# GD32F4xx register map
File version: 1.0
CPU: CM4 r2p1, little endian, MPU, FPU, 4 interrupt priority bits
Registers are 32-bit, read-write, reset 0x0 unless marked. A register's access mark holds for its fields unless they carry their own. Offsets are from the block's base; [hi:lo] are bit positions.

## I2C0 — Inter integrated circuit
Base 0x40005400
Same registers: I2C1 0x40005800, I2C2 0x40005C00
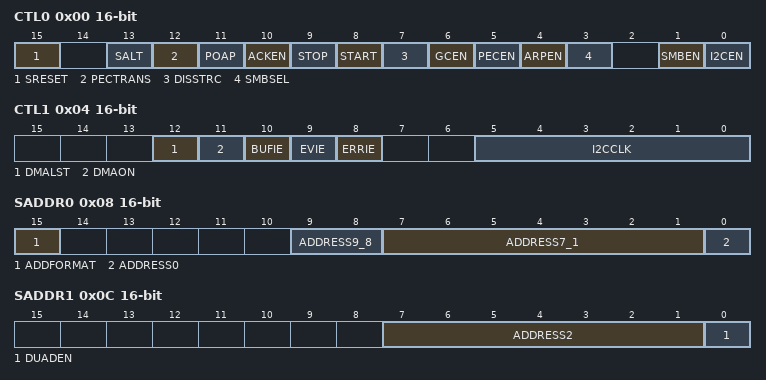
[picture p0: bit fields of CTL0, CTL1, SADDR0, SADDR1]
0x00 CTL0 16-bit — Control register 0
  [15] SRESET — Software reset
  [13] SALT — SMBus alert
  [12] PECTRANS — PEC Transfer
  [11] POAP — Position of ACK and PEC when receiving
  [10] ACKEN — Whether or not to send an ACK
  [9] STOP — Generate a STOP condition on I2C bus
  [8] START — Generate a START condition on I2C bus
  [7] DISSTRC — Whether to stretch SCL low when data is not ready in slave mode
  [6] GCEN — Whether or not to response to a General Call (0x00)
  [5] PECEN — PEC Calculation Switch
  [4] ARPEN — ARP protocol in SMBus switch
  [3] SMBSEL — SMBusType Selection
  [1] SMBEN — SMBus/I2C mode switch
  [0] I2CEN — I2C peripheral enable
0x04 CTL1 16-bit — Control register 1
  [12] DMALST — Flag indicating DMA last transfer
  [11] DMAON — DMA mode switch
  [10] BUFIE — Buffer interrupt enable
  [9] EVIE — Event interrupt enable
  [8] ERRIE — Error interrupt enable
  [5:0] I2CCLK — I2C Peripheral clock frequency
0x08 SADDR0 16-bit — Slave address register 0
  [15] ADDFORMAT — Address mode for the I2C slave
  [9:8] ADDRESS9_8 — Highest two bits of a 10-bit address
  [7:1] ADDRESS7_1 — 7-bit address or bits 7:1 of a 10-bit address
  [0] ADDRESS0 — Bit 0 of a 10-bit address
0x0C SADDR1 16-bit — Slave address register 1
  [7:1] ADDRESS2 — Second I2C address for the slave in Dual-Address mode
  [0] DUADEN — Dual-Address mode switch
0x10 DATA 16-bit — Transfer buffer register
  [7:0] TRB — Transmission or reception data buffer register
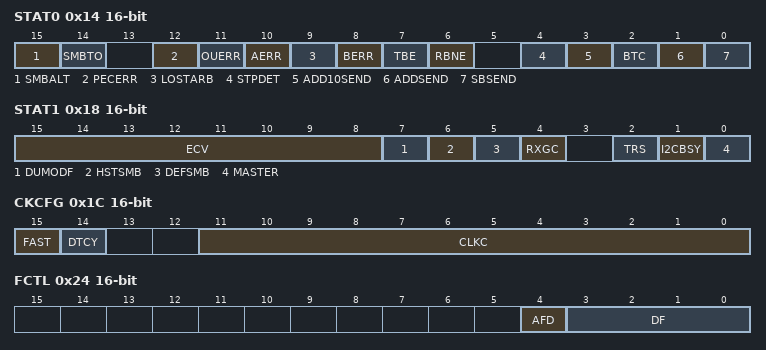
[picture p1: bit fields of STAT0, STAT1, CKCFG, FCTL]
0x14 STAT0 16-bit access per field — Transfer status register 0
  [15] SMBALT rw — SMBus Alert status
  [14] SMBTO rw — Timeout signal in SMBus mode
  [12] PECERR rw — PEC error when receiving data
  [11] OUERR rw — Over-run or under-run situation occurs in slave mode
  [10] AERR rw — Acknowledge error
  [9] LOSTARB rw — Arbitration Lost in master mode
  [8] BERR rw — A bus error occurs indication a unexpected START or STOP condition on I2C bus
  [7] TBE ro — I2C_DATA is Empty during transmitting
  [6] RBNE ro — I2C_DATA is not Empty during receiving
  [4] STPDET ro — STOP condition detected in slave mode
  [3] ADD10SEND ro — Header of 10-bit address is sent in master mode
  [2] BTC ro — Byte transmission completed
  [1] ADDSEND ro — Address is sent in master mode or received and matches in slave mode
  [0] SBSEND ro — START condition sent out in master mode
0x18 STAT1 16-bit ro — Transfer status register 1
  [15:8] ECV — Packet Error Checking Value that calculated by hardware when PEC is enabled
  [7] DUMODF — Dual Flag in slave mode
  [6] HSTSMB — SMBus Host Header detected in slave mode
  [5] DEFSMB — Default address of SMBusDevice
  [4] RXGC — General call address (00h) received
  [2] TRS — Whether the I2C is a transmitter or a receiver
  [1] I2CBSY — Busy flag
  [0] MASTER — A flag indicating whether I2C block is in master or slave mode
0x1C CKCFG 16-bit — Clock configure register
  [15] FAST — I2C speed selection in master mode
  [14] DTCY — Duty cycle in fast mode
  [11:0] CLKC — I2C Clock control in master mode
0x20 RT 16-bit reset 0x2 — Rise time register
  [5:0] RISETIME — Maximum rise time in master mode
0x24 FCTL 16-bit — Filter control register
  [4] AFD — Analog noise filter disable
  [3:0] DF — Digital noise filter
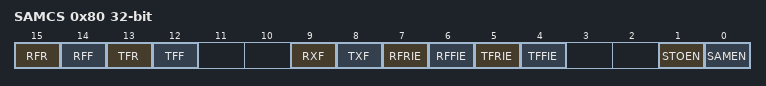
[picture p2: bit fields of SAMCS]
0x80 SAMCS access per field — SAM control and status register
  [15] RFR rw — Rxframe rise flag
  [14] RFF rw — Rxframe fall flag
  [13] TFR rw — Txframe rise flag
  [12] TFF rw — Txframe fall flag
  [9] RXF ro — Level of Rxframe signal
  [8] TXF ro — Level of Txframe signal
  [7] RFRIE rw — Rxframe rise interrupt enable
  [6] RFFIE rw — Rxframe fall interrupt enable
  [5] TFRIE rw — Txframe rise interrupt enable
  [4] TFFIE rw — Txframe fall interrupt enable
  [1] STOEN rw — SAM_V interface timeout detect enable
  [0] SAMEN rw — SAM_V interface enable
